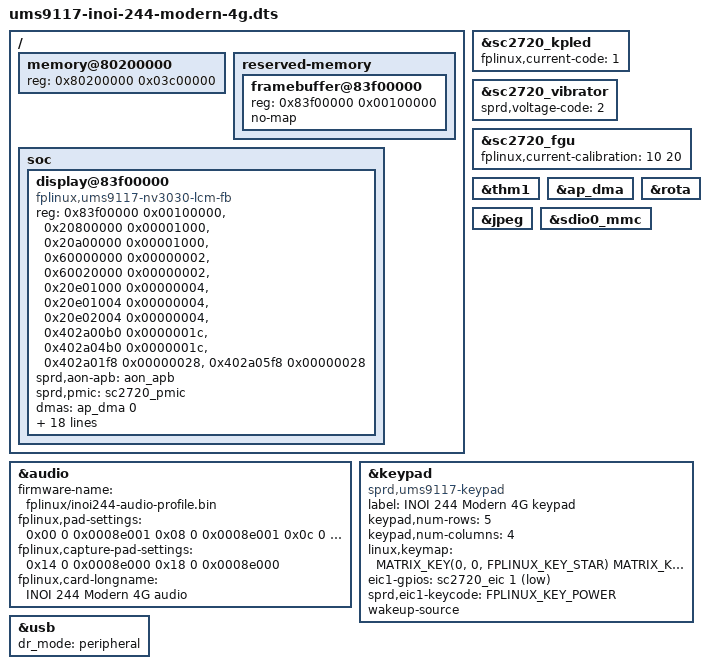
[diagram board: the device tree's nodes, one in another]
// SPDX-License-Identifier: GPL-2.0-only
/dts-v1/;

#include <dt-bindings/input/input.h>
#include <dt-bindings/input/fplinux-keypad.h>
#include <dt-bindings/gpio/gpio.h>
#include <dt-bindings/leds/common.h>
#include "ums9117.dtsi"
#include "ums9117-sc2720.dtsi"
#include "fplinux-target-identity.dtsi"
#include "inoi-244-modern-4g-nand-readonly.dtsi"
#include "inoi-244-modern-4g-bluetooth.dtsi"

/ {
	memory@80200000 {
		device_type = "memory";
		reg = <0x80200000 0x03c00000>;
	};

	reserved-memory {
		#address-cells = <1>;
		#size-cells = <1>;
		ranges;

		framebuffer@83f00000 {
			reg = <0x83f00000 0x00100000>;
			no-map;
		};
	};

	soc {
		display@83f00000 {
			compatible = "fplinux,ums9117-nv3030-lcm-fb";
			reg = <0x83f00000 0x00100000>,
			      <0x20800000 0x00001000>,
			      <0x20a00000 0x00001000>,
			      <0x60000000 0x00000002>,
			      <0x60020000 0x00000002>,
			      <0x20e01000 0x00000004>,
			      <0x20e01004 0x00000004>,
			      <0x20e02004 0x00000004>,
			      <0x402a00b0 0x0000001c>,
			      <0x402a04b0 0x0000001c>,
			      <0x402a01f8 0x00000028>,
			      <0x402a05f8 0x00000028>;
			reg-names = "framebuffer", "lcdc", "lcm", "lcm-command", "lcm-data",
				    "ap-ahb-gate-set", "ap-ahb-reset-set",
				    "ap-ahb-reset-clear", "pinmux", "pinconf",
				    "pinmux-data", "pinconf-data";
			sprd,aon-apb = <&aon_apb>;
			sprd,pmic = <&sc2720_pmic>;
			dmas = <&ap_dma 0>;
			dma-names = "copy";
			/* fpdoom cmd3001_inoi MCU timing at the 128 MHz AHB clock. */
			sprd,dbi-timing-ns = <5 150 150 30 80 120>;
			/* LCM control pins. */
			sprd,pinmux-offsets = <
				0x000 0x004 0x008 0x00c 0x010 0x014 0x018
			>;
			sprd,pinmux-values = <
				0 0 0x10 0x10 0x10 0x10 0x10
			>;
			sprd,pinconf-offsets = <
				0x000 0x004 0x008 0x00c 0x010 0x014 0x018
			>;
			sprd,pinconf-values = <
				0x00182001 0x00182046 0x00182001
				0x00182004 0x00182004 0x00182004 0x00182004
			>;
			/* Ten DBI data pins, separate from the intervening peripherals. */
			sprd,pinmux-data-offsets = <
				0x00 0x04 0x08 0x0c 0x10 0x14 0x18 0x1c 0x20 0x24
			>;
			sprd,pinmux-data-values = <
				0x10 0x10 0x10 0x10 0x10
				0x10 0x10 0x10 0x10 0x10
			>;
			sprd,pinconf-data-offsets = <
				0x00 0x04 0x08 0x0c 0x10 0x14 0x18 0x1c 0x20 0x24
			>;
			sprd,pinconf-data-values = <
				0x00182004 0x00182004 0x00182004 0x00182004 0x00182004
				0x00182004 0x00182004 0x00182004 0x00182004 0x00182004
			>;
			/* INOI uses RGB WLED channels only; the W channel stays dark. */
			sprd,wled-current-levels = <31 31 31 0>;
		};
	};
};

#include "ums9117-ram-session.dtsi"

&audio {
	firmware-name = "fplinux/inoi244-audio-profile.bin";
	fplinux,pad-settings = <
		0x00 0 0x0008e001
		0x08 0 0x0008e001
		0x0c 0 0x0008e001
		0x1c 0 0x0008e001
	>;
	fplinux,capture-pad-settings = <
		0x14 0 0x0008e000
		0x18 0 0x0008e000
	>;
	fplinux,card-longname = "INOI 244 Modern 4G audio";
	status = "okay";
};

&sc2720_kpled {
	fplinux,current-code = <1>;
};

&sc2720_vibrator {
	sprd,voltage-code = <2>;
};

&sc2720_fgu {
	fplinux,current-calibration = <10 20>;
};

&thm1 {
	status = "okay";
};

&ap_dma {
	status = "okay";
};

&rota {
	status = "okay";
};

&jpeg {
	status = "okay";
};

&sdio0_mmc {
	status = "okay";
};

&keypad {
	compatible = "sprd,ums9117-keypad";
	status = "okay";
	label = "INOI 244 Modern 4G keypad";
	keypad,num-rows = <5>;
	keypad,num-columns = <4>;
	linux,keymap = <
		MATRIX_KEY(0, 0, FPLINUX_KEY_STAR)
		MATRIX_KEY(0, 1, FPLINUX_KEY_0)
		MATRIX_KEY(0, 2, FPLINUX_KEY_POUND)
		MATRIX_KEY(0, 3, FPLINUX_KEY_OK)
		MATRIX_KEY(1, 0, FPLINUX_KEY_7)
		MATRIX_KEY(1, 1, FPLINUX_KEY_8)
		MATRIX_KEY(1, 2, FPLINUX_KEY_9)
		MATRIX_KEY(1, 3, FPLINUX_KEY_LEFT)
		MATRIX_KEY(2, 0, FPLINUX_KEY_4)
		MATRIX_KEY(2, 1, FPLINUX_KEY_5)
		MATRIX_KEY(2, 2, FPLINUX_KEY_6)
		MATRIX_KEY(2, 3, FPLINUX_KEY_RIGHT)
		MATRIX_KEY(3, 0, FPLINUX_KEY_1)
		MATRIX_KEY(3, 1, FPLINUX_KEY_2)
		MATRIX_KEY(3, 2, FPLINUX_KEY_3)
		MATRIX_KEY(3, 3, FPLINUX_KEY_DOWN)
		MATRIX_KEY(4, 0, FPLINUX_KEY_SOFT_LEFT)
		MATRIX_KEY(4, 1, FPLINUX_KEY_CALL)
		MATRIX_KEY(4, 2, FPLINUX_KEY_SOFT_RIGHT)
		MATRIX_KEY(4, 3, FPLINUX_KEY_UP)
	>;
	eic1-gpios = <&sc2720_eic 1 GPIO_ACTIVE_LOW>;
	sprd,eic1-keycode = <FPLINUX_KEY_POWER>;
	wakeup-source;
};

&usb {
	dr_mode = "peripheral";
	status = "okay";
};
